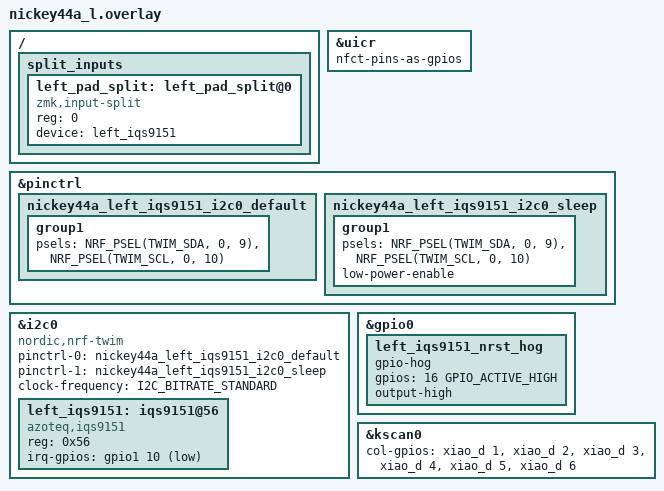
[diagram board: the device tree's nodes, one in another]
#include "nickey44a.dtsi"
#include <input/processors.dtsi>
#include <dt-bindings/pinctrl/nrf-pinctrl.h>
#include <zephyr/dt-bindings/input/input-event-codes.h>

/*
 * Left pad: LalaPad Gen2 trackpad (Azoteq IQS9151, I2C 0x56) on the former
 * TPS43 FPC breakout wiring:
 *   SDA  = XIAO NFC1/P0.09
 *   SCL  = XIAO NFC2/P0.10
 *   RDY  = XIAO P1.10 (IQS9151 RDY, active low)
 *   NRST = XIAO P0.16 (held high; leave unconnected if the module has none)
 * All events are forwarded unchanged; the right central maps them
 * (volume circle, Back/Forward, tab switching, clicks).
 */

&uicr {
    nfct-pins-as-gpios;
};

&pinctrl {
    nickey44a_left_iqs9151_i2c0_default: nickey44a_left_iqs9151_i2c0_default {
        group1 {
            psels = <NRF_PSEL(TWIM_SDA, 0, 9)>,
                    <NRF_PSEL(TWIM_SCL, 0, 10)>;
        };
    };

    nickey44a_left_iqs9151_i2c0_sleep: nickey44a_left_iqs9151_i2c0_sleep {
        group1 {
            psels = <NRF_PSEL(TWIM_SDA, 0, 9)>,
                    <NRF_PSEL(TWIM_SCL, 0, 10)>;
            low-power-enable;
        };
    };
};

/ {
    split_inputs {
        #address-cells = <1>;
        #size-cells = <0>;

        left_pad_split: left_pad_split@0 {
            compatible = "zmk,input-split";
            reg = <0>;
            device = <&left_iqs9151>;
        };
    };
};

&i2c0 {
    status = "okay";
    compatible = "nordic,nrf-twim";
    pinctrl-0 = <&nickey44a_left_iqs9151_i2c0_default>;
    pinctrl-1 = <&nickey44a_left_iqs9151_i2c0_sleep>;
    pinctrl-names = "default", "sleep";
    clock-frequency = <I2C_BITRATE_STANDARD>;
    #address-cells = <1>;
    #size-cells = <0>;

    left_iqs9151: iqs9151@56 {
        compatible = "azoteq,iqs9151";
        reg = <0x56>;
        status = "okay";
        /* IQS9151 RDY on the former TPS43 RDY line (P1.10). */
        irq-gpios = <&gpio1 10 (GPIO_ACTIVE_LOW | GPIO_PULL_UP)>;
    };
};

/*
 * The former TPS43 NRST line (P0.16) is driven high so an IQS9151 module
 * with NRST wired to it is never held in reset.
 */
&gpio0 {
    left_iqs9151_nrst_hog {
        gpio-hog;
        gpios = <16 GPIO_ACTIVE_HIGH>;
        output-high;
    };
};

&kscan0 {
        col-gpios
            = <&xiao_d 1 GPIO_ACTIVE_HIGH>
            , <&xiao_d 2 GPIO_ACTIVE_HIGH>
            , <&xiao_d 3 GPIO_ACTIVE_HIGH>
            , <&xiao_d 4 GPIO_ACTIVE_HIGH>
            , <&xiao_d 5 GPIO_ACTIVE_HIGH>
            , <&xiao_d 6 GPIO_ACTIVE_HIGH>
            ;
};
